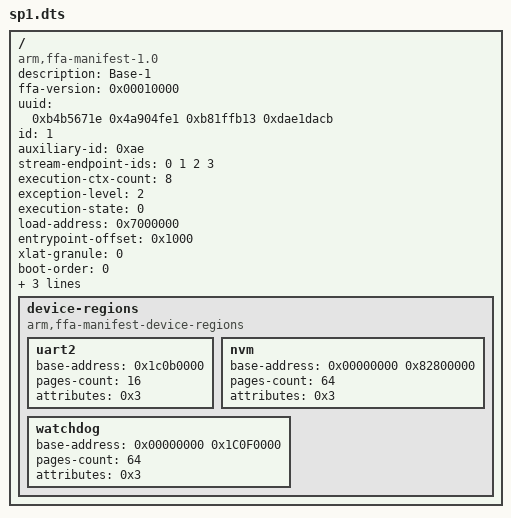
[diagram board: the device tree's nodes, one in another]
/*
 * Copyright (c) 2021, Arm Limited or its affiliates. All rights reserved.
 *
 * SPDX-License-Identifier: BSD-3-Clause
 *
 */

/dts-v1/;

/ {
    compatible = "arm,ffa-manifest-1.0";

    /* Properties */
    description = "Base-1";
    ffa-version = <0x00010000>; /* 31:16 - Major, 15:0 - Minor */
    uuid = <0xb4b5671e 0x4a904fe1 0xb81ffb13 0xdae1dacb>;
    id = <1>;
    auxiliary-id = <0xae>;
    stream-endpoint-ids = <0 1 2 3>;
    execution-ctx-count = <8>; /* Must be equal to no. of pe in system for EL1SP, otherwise set to 1 */
    exception-level = <2>; /* S-EL1 */
    execution-state = <0>; /* AARCH64 */
    load-address = <0x7000000>;
    entrypoint-offset = <0x1000>;
    xlat-granule = <0>; /* 4KiB */
    boot-order = <0>;
    messaging-method = <3>; /* Direct messaging only */
    run-time-model = <0>; /* Run to completion */

    /* Boot protocol */
    gp-register-num = <0x0>;

    device-regions {
        compatible = "arm,ffa-manifest-device-regions";

        uart2 {
            base-address = <0x1c0b0000>;
            pages-count = <16>;
            attributes = <0x3>; /* read-write */
        };

        nvm {
            base-address = <0x00000000 0x82800000>;
            pages-count = <64>;
            attributes = <0x3>; /* read-write */
        };

        watchdog {
            base-address = <0x00000000 0x1C0F0000>;
            pages-count = <64>;
            attributes = <0x3>; /* read-write */
        };

    };

};
